VERSION ""

NS_ :

BS_:

BU_: junction_box

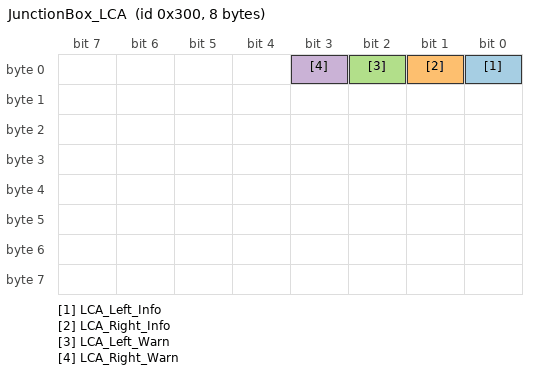
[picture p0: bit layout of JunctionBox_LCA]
BO_ 768 JunctionBox_LCA: 8 Vector__XXX
 SG_ LCA_Left_Info : 0|1@1+ (1,0) [0|1] "" Vector__XXX
 SG_ LCA_Right_Info : 1|1@1+ (1,0) [0|1] "" Vector__XXX
 SG_ LCA_Left_Warn : 2|1@1+ (1,0) [0|1] "" Vector__XXX
 SG_ LCA_Right_Warn : 3|1@1+ (1,0) [0|1] "" Vector__XXX

CM_ SG_ 768 LCA_Left_Info "Lane-change assist, left, informational (yellow)";
CM_ SG_ 768 LCA_Right_Info "Lane-change assist, right, informational (yellow)";
CM_ SG_ 768 LCA_Left_Warn "Lane-change assist, left, warning (red)";
CM_ SG_ 768 LCA_Right_Warn "Lane-change assist, right, warning (red)";
